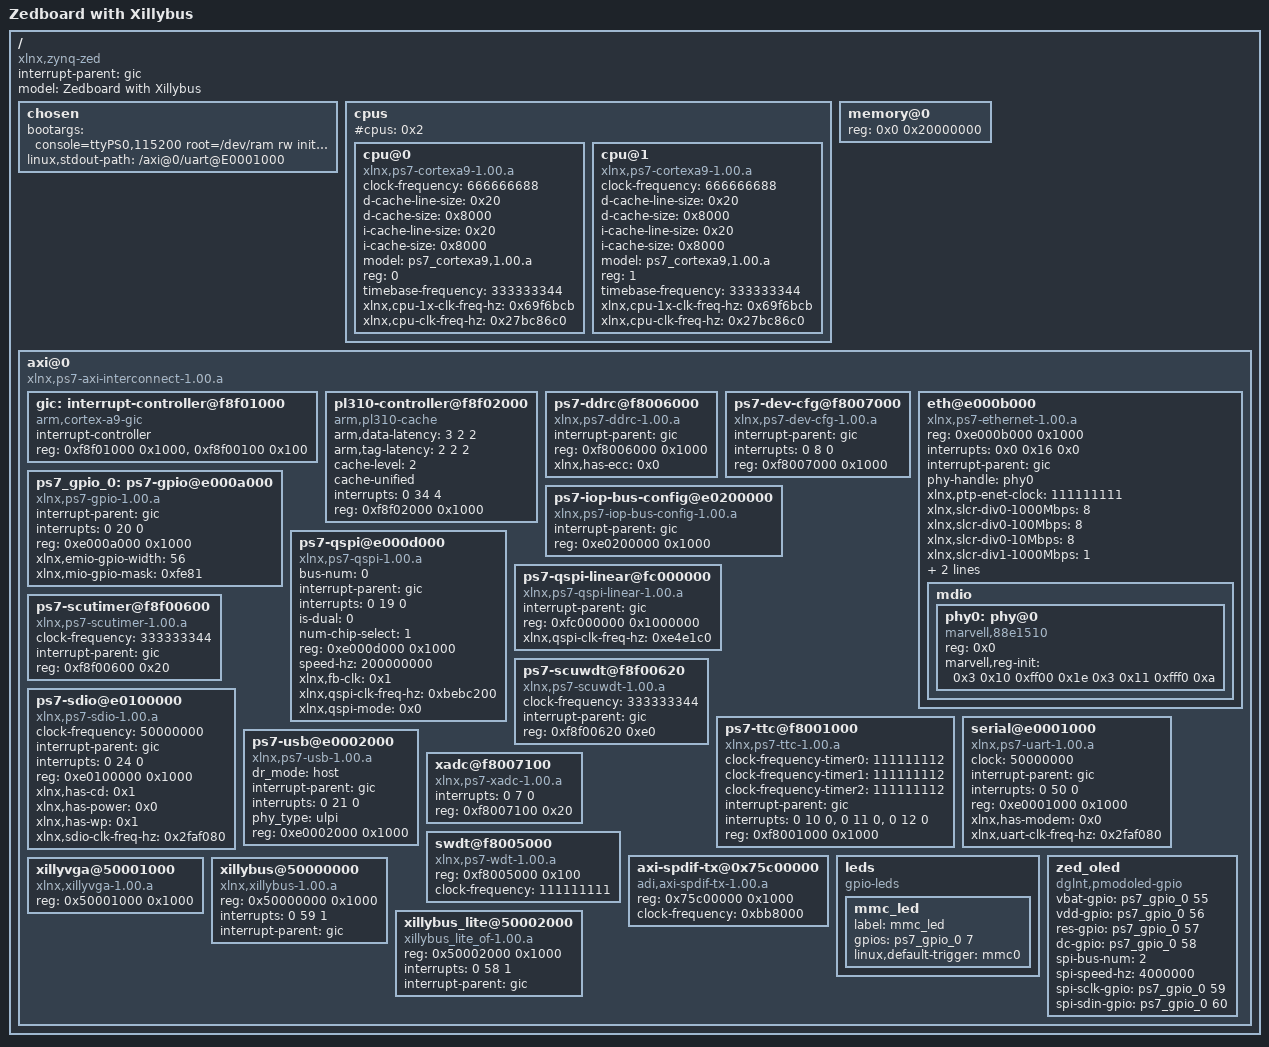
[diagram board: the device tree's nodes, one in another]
/dts-v1/;
/ {
	#address-cells = <1>;
	#size-cells = <1>;
	compatible = "xlnx,zynq-zed";
	interrupt-parent = <&gic>;
	model = "Zedboard with Xillybus";

	chosen {
      bootargs = "console=ttyPS0,115200 root=/dev/ram rw initrd=0x800000,8M earlyprintk rootfstype=ext4 rootwait devtmpfs.mount=0";
		linux,stdout-path = "/axi@0/uart@E0001000";
	};

	cpus {
		#address-cells = <1>;
		#cpus = <0x2>;
		#size-cells = <0>;
		cpu@0 {
			clock-frequency = <666666688>;
			compatible = "xlnx,ps7-cortexa9-1.00.a";
			d-cache-line-size = <0x20>;
			d-cache-size = <0x8000>;
			device_type = "cpu";
			i-cache-line-size = <0x20>;
			i-cache-size = <0x8000>;
			model = "ps7_cortexa9,1.00.a";
			reg = <0>;
			timebase-frequency = <333333344>;
			xlnx,cpu-1x-clk-freq-hz = <0x69f6bcb>;
			xlnx,cpu-clk-freq-hz = <0x27bc86c0>;
		} ;
		cpu@1 {
			clock-frequency = <666666688>;
			compatible = "xlnx,ps7-cortexa9-1.00.a";
			d-cache-line-size = <0x20>;
			d-cache-size = <0x8000>;
			device_type = "cpu";
			i-cache-line-size = <0x20>;
			i-cache-size = <0x8000>;
			model = "ps7_cortexa9,1.00.a";
			reg = <1>;
			timebase-frequency = <333333344>;
			xlnx,cpu-1x-clk-freq-hz = <0x69f6bcb>;
			xlnx,cpu-clk-freq-hz = <0x27bc86c0>;
		} ;
	} ;
	memory@0 {
		device_type = "memory";
		reg = < 0x0 0x20000000 >;
	} ;
	axi@0 {
		#address-cells = <1>;
		#size-cells = <1>;
		compatible = "xlnx,ps7-axi-interconnect-1.00.a", "simple-bus";
		ranges ;
		gic: interrupt-controller@f8f01000 {
			#interrupt-cells = < 3 >;
			compatible = "arm,cortex-a9-gic";
			interrupt-controller ;
			reg = < 0xf8f01000 0x1000  >,< 0xf8f00100 0x100  >;
		} ;
		pl310-controller@f8f02000 {
			arm,data-latency = < 3 2 2 >;
			arm,tag-latency = < 2 2 2 >;
			cache-level = < 2 >;
			cache-unified ;
			compatible = "arm,pl310-cache";
			interrupts = < 0 34 4 >;
			reg = < 0xf8f02000 0x1000 >;
		} ;
		ps7-ddrc@f8006000 {
			compatible = "xlnx,ps7-ddrc-1.00.a";
			interrupt-parent = <&gic>;
			reg = < 0xf8006000 0x1000 >;
			xlnx,has-ecc = <0x0>;
		} ;
		ps7-dev-cfg@f8007000 {
			compatible = "xlnx,ps7-dev-cfg-1.00.a";
			interrupt-parent = <&gic>;
			interrupts = < 0 8 0 >;
			reg = < 0xf8007000 0x1000 >;
		} ;

		eth@e000b000 {
			compatible = "xlnx,ps7-ethernet-1.00.a";
			reg = <0xe000b000 0x1000>;
			interrupts = <0x0 0x16 0x0>;
			interrupt-parent = <&gic>;
			phy-handle = <&phy0>;
			#address-cells = <0x1>;
			#size-cells = <0x0>;
			xlnx,ptp-enet-clock = <111111111>;
			xlnx,slcr-div0-1000Mbps = <8>;
			xlnx,slcr-div0-100Mbps = <8>;
			xlnx,slcr-div0-10Mbps = <8>;
			xlnx,slcr-div1-1000Mbps = <1>;
			xlnx,slcr-div1-100Mbps = <5>;
			xlnx,slcr-div1-10Mbps = <50>;
			mdio {
				#address-cells = <1>;
				#size-cells = <0>;

				phy0: phy@0 {
					compatible = "marvell,88e1510";
					device_type = "ethernet-phy";
					reg = <0x0>;
					marvell,reg-init = <0x3 0x10 0xff00 0x1e 0x3 0x11 0xfff0 0xa>;
				};
			};
		};

		ps7_gpio_0: ps7-gpio@e000a000 {
			compatible = "xlnx,ps7-gpio-1.00.a";
			#gpio-cells = <2>;
			interrupt-parent = <&gic>;
			interrupts = < 0 20 0 >;
			reg = < 0xe000a000 0x1000 >;
			xlnx,emio-gpio-width = < 56 >;
			xlnx,mio-gpio-mask = <0xfe81>;
		} ;
		ps7-iop-bus-config@e0200000 {
			compatible = "xlnx,ps7-iop-bus-config-1.00.a";
			interrupt-parent = <&gic>;
			reg = < 0xe0200000 0x1000 >;
		} ;
		ps7-qspi@e000d000 {
			bus-num = <0>;
			compatible = "xlnx,ps7-qspi-1.00.a";
			interrupt-parent = <&gic>;
			interrupts = < 0 19 0 >;
			is-dual = <0>;
			num-chip-select = <1>;
			reg = < 0xe000d000 0x1000 >;
			speed-hz = <200000000>;
			xlnx,fb-clk = <0x1>;
			xlnx,qspi-clk-freq-hz = <0xbebc200>;
			xlnx,qspi-mode = <0x0>;
		} ;
		ps7-qspi-linear@fc000000 {
			compatible = "xlnx,ps7-qspi-linear-1.00.a";
			interrupt-parent = <&gic>;
			reg = < 0xfc000000 0x1000000 >;
			xlnx,qspi-clk-freq-hz = <0xe4e1c0>;
		} ;
		ps7-scutimer@f8f00600 {
			clock-frequency = <333333344>;
			compatible = "xlnx,ps7-scutimer-1.00.a";
			interrupt-parent = <&gic>;
			reg = < 0xf8f00600 0x20 >;
		} ;
		ps7-scuwdt@f8f00620 {
			clock-frequency = <333333344>;
			compatible = "xlnx,ps7-scuwdt-1.00.a";
			interrupt-parent = <&gic>;
			reg = < 0xf8f00620 0xe0 >;
		} ;
		ps7-sdio@e0100000 {
			clock-frequency = <50000000>;
			compatible = "xlnx,ps7-sdio-1.00.a", "xlnx,ps7-sdhci-1.00.a", "generic-sdhci";
			interrupt-parent = <&gic>;
			interrupts = < 0 24 0 >;
			reg = < 0xe0100000 0x1000 >;
			xlnx,has-cd = <0x1>;
			xlnx,has-power = <0x0>;
			xlnx,has-wp = <0x1>;
			xlnx,sdio-clk-freq-hz = <0x2faf080>;
		} ;
		ps7-ttc@f8001000 {
			clock-frequency-timer0 = <111111112>;
			clock-frequency-timer1 = <111111112>;
			clock-frequency-timer2 = <111111112>;
			compatible = "xlnx,ps7-ttc-1.00.a";
			interrupt-parent = <&gic>;
			interrupts = < 0 10 0  >,< 0 11 0  >,< 0 12 0  >;
			reg = < 0xf8001000 0x1000 >;
		} ;
		serial@e0001000 {
			clock = <50000000>;
			compatible = "xlnx,ps7-uart-1.00.a", "xlnx,xuartps";
			device_type = "serial";
			interrupt-parent = <&gic>;
			interrupts = < 0 50 0 >;
			reg = < 0xe0001000 0x1000 >;
			xlnx,has-modem = <0x0>;
			xlnx,uart-clk-freq-hz = <0x2faf080>;
		} ;
		ps7-usb@e0002000 {
			compatible = "xlnx,ps7-usb-1.00.a";
			dr_mode = "host";
			interrupt-parent = <&gic>;
			interrupts = < 0 21 0 >;
			phy_type = "ulpi";
			reg = < 0xe0002000 0x1000 >;
		} ;
		xadc@f8007100 {
			compatible = "xlnx,ps7-xadc-1.00.a";
			interrupts = < 0 7 0 >;
			reg = < 0xf8007100 0x20 >;
		} ;

		swdt@f8005000 {
			device_type = "watchdog";
			compatible = "xlnx,ps7-wdt-1.00.a";
			reg = <0xf8005000 0x100>;
			clock-frequency = <111111111>;
		};

		axi-spdif-tx@0x75c00000 {
			compatible = "adi,axi-spdif-tx-1.00.a";
			reg = <0x75c00000 0x1000>;
			clock-frequency = <0xbb8000>;
		};

		leds {
			compatible = "gpio-leds";

			mmc_led {
				label = "mmc_led";
				gpios = <&ps7_gpio_0 7 0>;
				linux,default-trigger = "mmc0";
			};
		};

		zed_oled {
			compatible = "dglnt,pmodoled-gpio";
			/* GPIO Pins */
			vbat-gpio = <&ps7_gpio_0 55 0>;
			vdd-gpio = <&ps7_gpio_0 56 0>;
			res-gpio = <&ps7_gpio_0 57 0>;
			dc-gpio = <&ps7_gpio_0 58 0>;
			/* SPI-GPIOs */
			spi-bus-num = <2>;
			spi-speed-hz = <4000000>;
			spi-sclk-gpio = <&ps7_gpio_0 59 0>;
			spi-sdin-gpio = <&ps7_gpio_0 60 0>;
		};

	// Xillybus related:

		xillyvga@50001000 {
			compatible = "xlnx,xillyvga-1.00.a";
			reg = < 0x50001000 0x1000 >;
		} ;
		xillybus@50000000 {
			compatible = "xlnx,xillybus-1.00.a";
			reg = < 0x50000000 0x1000 >;
			interrupts = < 0 59 1 >;
			interrupt-parent = <&gic>;
		} ;
		xillybus_lite@50002000 {
			compatible = "xillybus_lite_of-1.00.a";
			reg = < 0x50002000 0x1000 >;
			interrupts = < 0 58 1 >;
			interrupt-parent = <&gic>;
		} ;

	} ;
} ;
